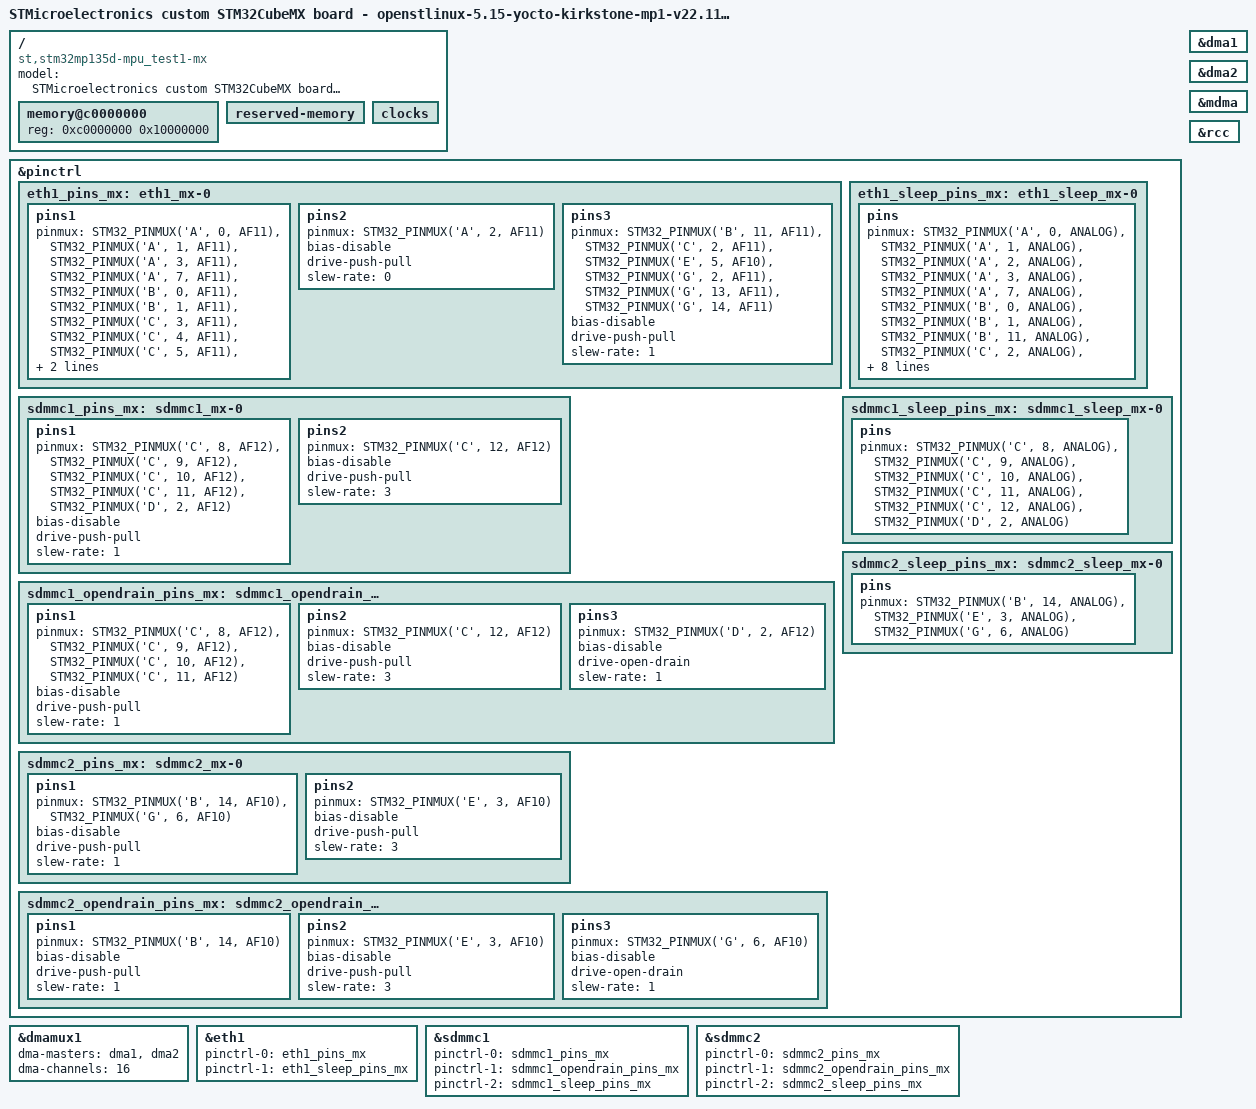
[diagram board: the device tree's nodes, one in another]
/* SPDX-License-Identifier: (GPL-2.0+ OR BSD-3-Clause) */
/*
 * Copyright (C) STMicroelectronics 2023 - All Rights Reserved
 * Author: STM32CubeMX code generation for STMicroelectronics.
 */

/* For more information on Device Tree configuration, please refer to
 * https://wiki.st.com/stm32mpu/wiki/Category:Device_tree_configuration
 */

/dts-v1/;
#include <dt-bindings/pinctrl/stm32-pinfunc.h>

#include "stm32mp135.dtsi"
#include "stm32mp13xd.dtsi"

/* USER CODE BEGIN includes */
/* USER CODE END includes */

/ {
	model = "STMicroelectronics custom STM32CubeMX board - openstlinux-5.15-yocto-kirkstone-mp1-v22.11.23";
	compatible = "st,stm32mp135d-mpu_test1-mx", "st,stm32mp135";

	memory@c0000000 {
		device_type = "memory";
		reg = <0xc0000000 0x10000000>;

		/* USER CODE BEGIN memory */
		/* USER CODE END memory */
	};

	reserved-memory {
		#address-cells = <1>;
		#size-cells = <1>;
		ranges;

		/* USER CODE BEGIN reserved-memory */
		/* USER CODE END reserved-memory */
	};

	/* USER CODE BEGIN root */
	/* USER CODE END root */

	clocks {

		/* USER CODE BEGIN clocks */
		/* USER CODE END clocks */
	};

}; /*root*/

&pinctrl {

	eth1_pins_mx: eth1_mx-0 {
		pins1 {
			pinmux = <STM32_PINMUX('A', 0, AF11)>, /* ETH1_CRS */
					 <STM32_PINMUX('A', 1, AF11)>, /* ETH1_RX_CLK */
					 <STM32_PINMUX('A', 3, AF11)>, /* ETH1_COL */
					 <STM32_PINMUX('A', 7, AF11)>, /* ETH1_RX_DV */
					 <STM32_PINMUX('B', 0, AF11)>, /* ETH1_RXD2 */
					 <STM32_PINMUX('B', 1, AF11)>, /* ETH1_RXD3 */
					 <STM32_PINMUX('C', 3, AF11)>, /* ETH1_TX_CLK */
					 <STM32_PINMUX('C', 4, AF11)>, /* ETH1_RXD0 */
					 <STM32_PINMUX('C', 5, AF11)>, /* ETH1_RXD1 */
					 <STM32_PINMUX('H', 6, AF11)>; /* ETH1_RX_ER */
			bias-disable;
		};
		pins2 {
			pinmux = <STM32_PINMUX('A', 2, AF11)>; /* ETH1_MDIO */
			bias-disable;
			drive-push-pull;
			slew-rate = <0>;
		};
		pins3 {
			pinmux = <STM32_PINMUX('B', 11, AF11)>, /* ETH1_TX_EN */
					 <STM32_PINMUX('C', 2, AF11)>, /* ETH1_TXD2 */
					 <STM32_PINMUX('E', 5, AF10)>, /* ETH1_TXD3 */
					 <STM32_PINMUX('G', 2, AF11)>, /* ETH1_MDC */
					 <STM32_PINMUX('G', 13, AF11)>, /* ETH1_TXD0 */
					 <STM32_PINMUX('G', 14, AF11)>; /* ETH1_TXD1 */
			bias-disable;
			drive-push-pull;
			slew-rate = <1>;
		};
	};

	eth1_sleep_pins_mx: eth1_sleep_mx-0 {
		pins {
			pinmux = <STM32_PINMUX('A', 0, ANALOG)>, /* ETH1_CRS */
					 <STM32_PINMUX('A', 1, ANALOG)>, /* ETH1_RX_CLK */
					 <STM32_PINMUX('A', 2, ANALOG)>, /* ETH1_MDIO */
					 <STM32_PINMUX('A', 3, ANALOG)>, /* ETH1_COL */
					 <STM32_PINMUX('A', 7, ANALOG)>, /* ETH1_RX_DV */
					 <STM32_PINMUX('B', 0, ANALOG)>, /* ETH1_RXD2 */
					 <STM32_PINMUX('B', 1, ANALOG)>, /* ETH1_RXD3 */
					 <STM32_PINMUX('B', 11, ANALOG)>, /* ETH1_TX_EN */
					 <STM32_PINMUX('C', 2, ANALOG)>, /* ETH1_TXD2 */
					 <STM32_PINMUX('C', 3, ANALOG)>, /* ETH1_TX_CLK */
					 <STM32_PINMUX('C', 4, ANALOG)>, /* ETH1_RXD0 */
					 <STM32_PINMUX('C', 5, ANALOG)>, /* ETH1_RXD1 */
					 <STM32_PINMUX('E', 5, ANALOG)>, /* ETH1_TXD3 */
					 <STM32_PINMUX('G', 2, ANALOG)>, /* ETH1_MDC */
					 <STM32_PINMUX('G', 13, ANALOG)>, /* ETH1_TXD0 */
					 <STM32_PINMUX('G', 14, ANALOG)>, /* ETH1_TXD1 */
					 <STM32_PINMUX('H', 6, ANALOG)>; /* ETH1_RX_ER */
		};
	};

	sdmmc1_pins_mx: sdmmc1_mx-0 {
		pins1 {
			pinmux = <STM32_PINMUX('C', 8, AF12)>, /* SDMMC1_D0 */
					 <STM32_PINMUX('C', 9, AF12)>, /* SDMMC1_D1 */
					 <STM32_PINMUX('C', 10, AF12)>, /* SDMMC1_D2 */
					 <STM32_PINMUX('C', 11, AF12)>, /* SDMMC1_D3 */
					 <STM32_PINMUX('D', 2, AF12)>; /* SDMMC1_CMD */
			bias-disable;
			drive-push-pull;
			slew-rate = <1>;
		};
		pins2 {
			pinmux = <STM32_PINMUX('C', 12, AF12)>; /* SDMMC1_CK */
			bias-disable;
			drive-push-pull;
			slew-rate = <3>;
		};
	};

	sdmmc1_opendrain_pins_mx: sdmmc1_opendrain_mx-0 {
		pins1 {
			pinmux = <STM32_PINMUX('C', 8, AF12)>, /* SDMMC1_D0 */
					 <STM32_PINMUX('C', 9, AF12)>, /* SDMMC1_D1 */
					 <STM32_PINMUX('C', 10, AF12)>, /* SDMMC1_D2 */
					 <STM32_PINMUX('C', 11, AF12)>; /* SDMMC1_D3 */
			bias-disable;
			drive-push-pull;
			slew-rate = <1>;
		};
		pins2 {
			pinmux = <STM32_PINMUX('C', 12, AF12)>; /* SDMMC1_CK */
			bias-disable;
			drive-push-pull;
			slew-rate = <3>;
		};
		pins3 {
			pinmux = <STM32_PINMUX('D', 2, AF12)>; /* SDMMC1_CMD */
			bias-disable;
			drive-open-drain;
			slew-rate = <1>;
		};
	};

	sdmmc1_sleep_pins_mx: sdmmc1_sleep_mx-0 {
		pins {
			pinmux = <STM32_PINMUX('C', 8, ANALOG)>, /* SDMMC1_D0 */
					 <STM32_PINMUX('C', 9, ANALOG)>, /* SDMMC1_D1 */
					 <STM32_PINMUX('C', 10, ANALOG)>, /* SDMMC1_D2 */
					 <STM32_PINMUX('C', 11, ANALOG)>, /* SDMMC1_D3 */
					 <STM32_PINMUX('C', 12, ANALOG)>, /* SDMMC1_CK */
					 <STM32_PINMUX('D', 2, ANALOG)>; /* SDMMC1_CMD */
		};
	};

	sdmmc2_pins_mx: sdmmc2_mx-0 {
		pins1 {
			pinmux = <STM32_PINMUX('B', 14, AF10)>, /* SDMMC2_D0 */
					 <STM32_PINMUX('G', 6, AF10)>; /* SDMMC2_CMD */
			bias-disable;
			drive-push-pull;
			slew-rate = <1>;
		};
		pins2 {
			pinmux = <STM32_PINMUX('E', 3, AF10)>; /* SDMMC2_CK */
			bias-disable;
			drive-push-pull;
			slew-rate = <3>;
		};
	};

	sdmmc2_opendrain_pins_mx: sdmmc2_opendrain_mx-0 {
		pins1 {
			pinmux = <STM32_PINMUX('B', 14, AF10)>; /* SDMMC2_D0 */
			bias-disable;
			drive-push-pull;
			slew-rate = <1>;
		};
		pins2 {
			pinmux = <STM32_PINMUX('E', 3, AF10)>; /* SDMMC2_CK */
			bias-disable;
			drive-push-pull;
			slew-rate = <3>;
		};
		pins3 {
			pinmux = <STM32_PINMUX('G', 6, AF10)>; /* SDMMC2_CMD */
			bias-disable;
			drive-open-drain;
			slew-rate = <1>;
		};
	};

	sdmmc2_sleep_pins_mx: sdmmc2_sleep_mx-0 {
		pins {
			pinmux = <STM32_PINMUX('B', 14, ANALOG)>, /* SDMMC2_D0 */
					 <STM32_PINMUX('E', 3, ANALOG)>, /* SDMMC2_CK */
					 <STM32_PINMUX('G', 6, ANALOG)>; /* SDMMC2_CMD */
		};
	};

	/* USER CODE BEGIN pinctrl */
	/* USER CODE END pinctrl */
};

&dma1{
	status = "okay";

	/* USER CODE BEGIN dma1 */
	/* USER CODE END dma1 */
};

&dma2{
	status = "okay";

	/* USER CODE BEGIN dma2 */
	/* USER CODE END dma2 */
};

&dmamux1{
	status = "okay";

	dma-masters = <&dma1 &dma2>;
	dma-channels = <16>;

	/* USER CODE BEGIN dmamux1 */
	/* USER CODE END dmamux1 */
};

&eth1{
	pinctrl-names = "default", "sleep";
	pinctrl-0 = <&eth1_pins_mx>;
	pinctrl-1 = <&eth1_sleep_pins_mx>;
	status = "okay";

	/* USER CODE BEGIN eth1 */
	/* USER CODE END eth1 */
};

&mdma{
	status = "okay";

	/* USER CODE BEGIN mdma */
	/* USER CODE END mdma */
};

&rcc{
	status = "okay";

	/* USER CODE BEGIN rcc */
	/* USER CODE END rcc */
};

&sdmmc1{
	pinctrl-names = "default", "opendrain", "sleep";
	pinctrl-0 = <&sdmmc1_pins_mx>;
	pinctrl-1 = <&sdmmc1_opendrain_pins_mx>;
	pinctrl-2 = <&sdmmc1_sleep_pins_mx>;
	status = "okay";

	/* USER CODE BEGIN sdmmc1 */
	/* USER CODE END sdmmc1 */
};

&sdmmc2{
	pinctrl-names = "default", "opendrain", "sleep";
	pinctrl-0 = <&sdmmc2_pins_mx>;
	pinctrl-1 = <&sdmmc2_opendrain_pins_mx>;
	pinctrl-2 = <&sdmmc2_sleep_pins_mx>;
	status = "okay";

	/* USER CODE BEGIN sdmmc2 */
	/* USER CODE END sdmmc2 */
};

/* USER CODE BEGIN addons */
/* USER CODE END addons */

